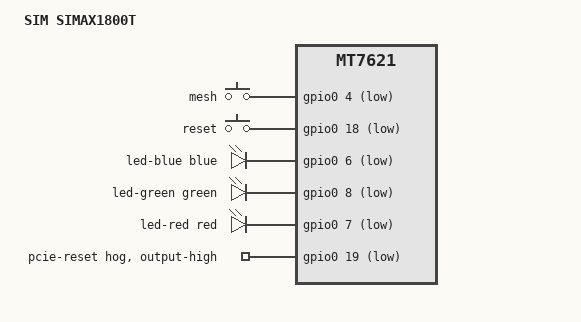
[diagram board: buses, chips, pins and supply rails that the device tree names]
// SPDX-License-Identifier: GPL-2.0-or-later

/dts-v1/;

#include "mt7621.dtsi"

#include <dt-bindings/gpio/gpio.h>
#include <dt-bindings/input/input.h>
#include <dt-bindings/leds/common.h>

/ {
	compatible = "sim,simax1800t", "mediatek,mt7621-soc";
	model = "SIM SIMAX1800T";

	/delete-node/ clock-48m;
	/delete-node/ clock-50m;
	/delete-node/ watchdog@1e000100;
	/delete-node/ spi@1e000b00;
	/delete-node/ serial@1e000d00;
	/delete-node/ serial@1e000e00;
	/delete-node/ mmc@1e130000;
	/delete-node/ usb@1e1c0000;
	/delete-node/ usb-phy@1e1d0000;

	aliases {
		serial0 = &uart0;
	};

	chosen {
		stdout-path = "serial0:115200n8";
	};

	gpio-keys {
		compatible = "gpio-keys";

		button-mesh {
			label = "mesh";
			linux,code = <KEY_WPS_BUTTON>;
			gpios = <&gpio0 4 GPIO_ACTIVE_LOW>;
		};

		button-reset {
			label = "reset";
			linux,code = <KEY_RESTART>;
			gpios = <&gpio0 18 GPIO_ACTIVE_LOW>;
		};
	};

	gpio-leds {
		compatible = "gpio-leds";

		led-blue {
			color = <LED_COLOR_ID_BLUE>;
			function = LED_FUNCTION_STATUS;
			gpios = <&gpio0 6 GPIO_ACTIVE_LOW>;
			default-state = "off";
		};

		led-green {
			color = <LED_COLOR_ID_GREEN>;
			function = LED_FUNCTION_STATUS;
			gpios = <&gpio0 8 GPIO_ACTIVE_LOW>;
			default-state = "on";
		};

		led-red {
			color = <LED_COLOR_ID_RED>;
			function = LED_FUNCTION_STATUS;
			gpios = <&gpio0 7 GPIO_ACTIVE_LOW>;
			default-state = "off";
		};
	};

	options {
		u-boot {
			compatible = "u-boot,config";
			boot-btn1 = "mesh";
			boot-btn2 = "reset";
			boot-led1 = "green:status";
			boot-led2 = "red:status";
			bootcmd_1-1 = "tftp_boot_ik";
			bootcmd_1-2 = "tftp_update_fw";
			bootcmd_1-3 = "switch_console";
			bootcmd_1-4 = "env init";
			bootcmd_2-1 = "tftp_boot_ik";
			bootcmd_2-2 = "tftp_update_fw";
			bootcmd_2-3 = "switch_console";
			bootcmd_2-4 = "switch_ubi";
		};
	};
};

&gpio0 {
	pcie-reset {
		gpio-hog;
		gpios = <19 GPIO_ACTIVE_LOW>;
		output-high;
	};
};

&pinctrl {
	pinctrl-0 = <&state_default>, <&nand_pins>;

	/delete-node/ uart2_pins;
	/delete-node/ uart3_pins;
	/delete-node/ sdxc_pins;
	/delete-node/ spi_pins;
};

&state_default {
	/delete-node/ rgmii2-gpio_pins;
	/delete-node/ sdxc-gpio_pins;
};
